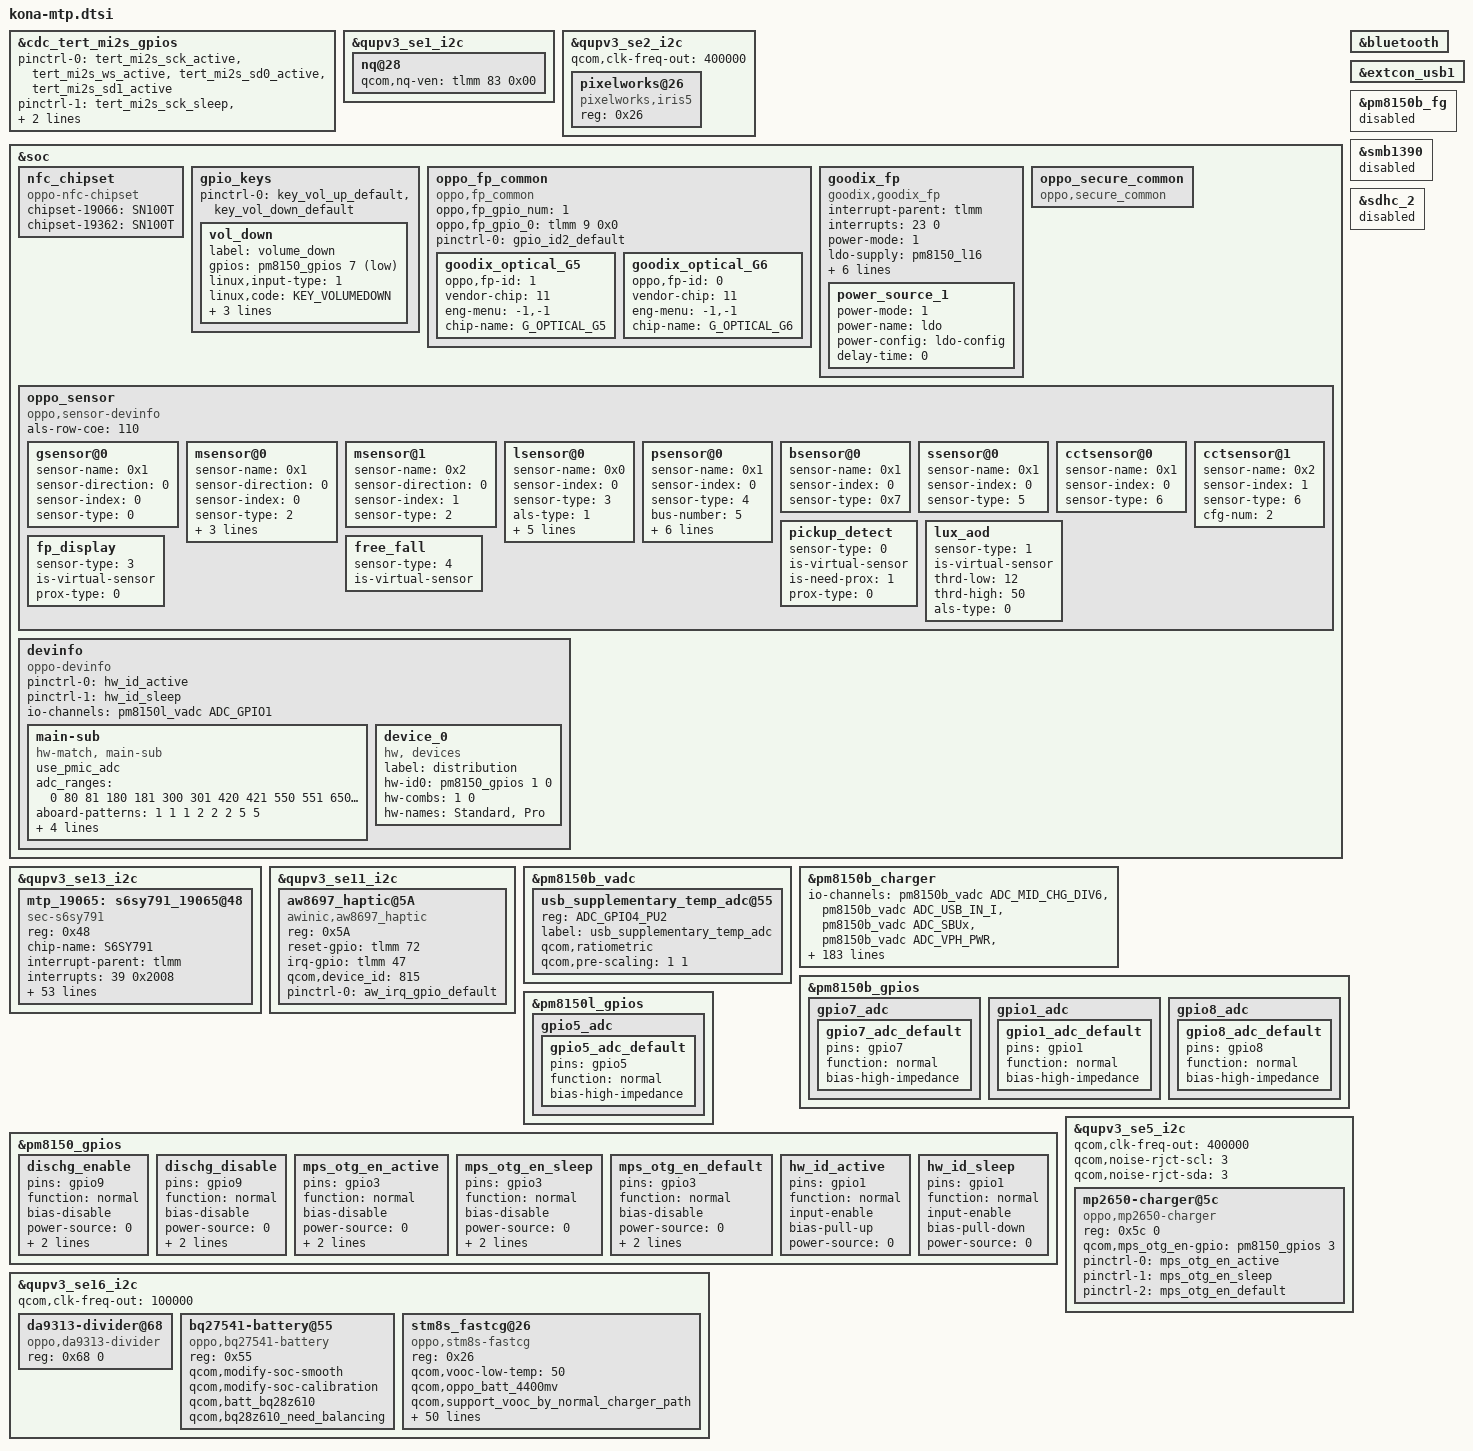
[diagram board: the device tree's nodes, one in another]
#include "kona-audio-overlay.dtsi"
#include "kona-camera-sensor-19066.dtsi"
#include "kona-pmic-overlay.dtsi"
#include "kona-sde-display.dtsi"

&cdc_tert_mi2s_gpios {
	pinctrl-0 = <&tert_mi2s_sck_active &tert_mi2s_ws_active
				&tert_mi2s_sd0_active &tert_mi2s_sd1_active>;
	pinctrl-1 = <&tert_mi2s_sck_sleep &tert_mi2s_ws_sleep
				&tert_mi2s_sd0_sleep &tert_mi2s_sd1_sleep>;
};

&qupv3_se1_i2c {
	/delete-property/ qcom,clk-freq-out;

	nq@28 {
		qcom,nq-ven = <&tlmm 83 0x00>;
	};
};

&qupv3_se2_i2c {
	status = "ok";
	qcom,clk-freq-out = <400000>;
	pixelworks@26 {  //i2c: 22, i3c: 26
		status = "ok";
		compatible = "pixelworks,iris5";
		reg = <0x26>;
	};
};

&soc {
	nfc_chipset {
		compatible = "oppo-nfc-chipset";
		chipset-19066 = "SN100T";
		chipset-19362 = "SN100T";
	};

	gpio_keys {
		pinctrl-0 = <&key_vol_up_default &key_vol_down_default>;

		vol_down {
			label = "volume_down";
			gpios = <&pm8150_gpios  7 GPIO_ACTIVE_LOW>;
			linux,input-type = <1>;
			linux,code = <KEY_VOLUMEDOWN>;
			gpio-key,wakeup;
			debounce-interval = <15>;
			linux,can-disable;
		};
	};

	oppo_fp_common {
		compatible = "oppo,fp_common";
		oppo,fp_gpio_num = <1>; /* the gpio number of fingerprint id used */
		oppo,fp_gpio_0 = <&tlmm 9 0x0>;
				pinctrl-names = "default";
		pinctrl-0 = <&gpio_id2_default>;
		goodix_optical_G5 {
			oppo,fp-id = <1>; /* fp id mapping table */
			vendor-chip = <11>; /* please refer to the struct fp_vendor_t in oppo_fp_commmon.n */
			eng-menu = "-1,-1"; /* represents SNR, inclination test item in engineer menu, and 0/1 means off/on */
			chip-name = "G_OPTICAL_G5";  /* /proc/fp_id, will be displayed in engineer menu  */
		};
		goodix_optical_G6 {
			oppo,fp-id = <0>; /* fp id mapping table */
			vendor-chip = <11>; /* please refer to the struct fp_vendor_t in oppo_fp_commmon.n */
			eng-menu = "-1,-1"; /* represents SNR, inclination test item in engineer menu, and 0/1 means off/on */
			chip-name = "G_OPTICAL_G6";  /* /proc/fp_id, will be displayed in engineer menu  */
		};
	};

	goodix_fp {
		status = "ok";
		compatible = "goodix,goodix_fp";
		interrupt-parent = <&tlmm>;
		interrupts = <23 0>;
		power-mode = <1> ; /*please refer to the struct fp_power_mode_t in oppo_fp_commmon.n ,0: power mode not set, 1: ldo power, 2: gpio power, 3: auto power */
		ldo-supply = <&pm8150_l16>;
		ldo-config = <3300000 3300000 150000>;
		goodix,gpio_irq = <&tlmm 23 0x1>;
		goodix,gpio_reset = <&tlmm 68 0x0>;
		pinctrl-names = "default";
		pinctrl-0 = <&gpio_goodix_irq_default>;
		notify_tpinfo_flag = <1>;
		power-num = <1>;
		power_source_1 {
			power-mode = <1>;
			power-name = "ldo";
			power-config = "ldo-config";
			delay-time = <0>;
		};
	};

	oppo_secure_common {
		compatible = "oppo,secure_common";
	};

	/*enum sensor_id { OPPO_ACCEL,OPPO_GYRO,OPPO_MAG,OPPO_LIGHT,OPPO_PROXIMITY,OPPO_SAR,OPPO_CT,OPPO_BAROMETER,SENSORS_NUM};*/
	oppo_sensor {
		compatible = "oppo,sensor-devinfo";
		als-row-coe = <110>;
		/*enum {LSM6DSM = 0x01, BMI160 = 0x02, LSM6DS3 = 0x04};*/
		gsensor@0 {
			sensor-name = <0x1>;//LSM6DSM
			sensor-direction = <0>;
			sensor-index = <0>;//source num
			sensor-type = <0>;//OPPO_ACCEL
		};
		/* enum {AKM0991X = 0x01, MMC5603 = 0x02};*/
		msensor@0 {
			sensor-name = <0x1>;//AKM09918
			sensor-direction = <0>;
			sensor-index = <0>;
			sensor-type = <2>;//OPPO_MAG
			parameter-number= <18>;
			//sensor-parameter = <1>;//0-useless;other- to differ special parameter
			soft-mag-parameter = <9887 0 1457 0 73 0 1262 0 10096 0 283 1 933 0 663 1 10867 0>;//e00 sign e01 sign...
		};
		msensor@1 {
			sensor-name = <0x2>;//MMC5603
			sensor-direction = <0>;
			sensor-index = <1>;
			sensor-type = <2>;//OPPO_MAG
		};
		/*enum {STK3A5X=0x01,TCS3701=0x02,TCS3408=0x04};*/
		lsensor@0 {
			sensor-name = <0x0>;//TCS3408 0-use other driver//compatible old
			sensor-index = <0>;
			sensor-type = <3>;//OPPO_LIGHT
			als-type = <1>;
			is-unit-device = <0>;
			is-als-dri = <0>;
			als-factor = <110>;
			is_als_initialed = <0>;
			als_buffer_length = <10>;
		};
		psensor@0 {
			sensor-name = <0x1>;//STK33502
			sensor-index = <0>;
			sensor-type = <4>;//OPPO_PROXIMITY
			bus-number = <5>;
			irq-number = <122>;
			ps-type = <1>;
			ps_saturation = <2600>;
			/*1-need close 2-close has contidition 0-not close*/
			is_need_close_pd = <2>;
			sn_number = <0xf2950863 0x09347b81 0xa5d679f5 0x5fe0fa1b 0xfcfb33ca
					0x85df9dee 0x30682ac0 0xddf4bc3d 0xb8d72979 0xe83f0a90
					0x24a9bcf0 0x77d4a0f0 0xb6870ef3 0x15e9693b 0x21858a59
					0x35a15be7 0x6c682a71 0x45e3d4ee>;
		};
		/*enum {LPS22HH = 0x01, BMP380 = 0x02}*/
		bsensor@0 {
			sensor-name = <0x1>;//LPS22HH
			sensor-index = <0>;
			sensor-type = <0x7>;//OPPO_BAROMETER
		};
		/* enum {SX9324 = 0x01} */
		ssensor@0 {
			sensor-name = <0x1>;//SX9324
			sensor-index = <0>;
			sensor-type = <5>;//OPPO_SAR
		};
		/* enum {tcs3408 = 0x01 tcs3408_rear = 0x02} */
		cctsensor@0 {
			sensor-name = <0x1>; //tcs3408
			sensor-index = <0>;
			sensor-type = <6>; //OPPO_CT
		};
		cctsensor@1 {
			sensor-name = <0x2>; //tcs3408_rear
			sensor-index = <1>;
			sensor-type = <6>; //OPPO_CT
			cfg-num = <2>;
		};
		/*virtual sensor
		enum sensor_algo_id {
			OPPO_PICKUP_DETECT,
			OPPO_LUX_AOD,
			OPPO_TP_GESTURE,
			OPPO_FP_DISPLAY,
			OPPO_FREE_FALL,
			OPPO_CAMERA_PROTECT,
			SENSOR_ALGO_NUM
		}*/
		pickup_detect {
			sensor-type = <0>;//OPPO_PICKUP_DETECT
			is-virtual-sensor;
			is-need-prox = <1>;
			prox-type = <0>;
		};
		lux_aod {
			sensor-type = <1>; //OPPO_LUX_AOD
			is-virtual-sensor;
			thrd-low = <12>;
			thrd-high = <50>;
			als-type = <0>;
		};
		fp_display {
			sensor-type = <3>;//OPPO_FP_DISPLAY
			is-virtual-sensor;
			prox-type = <0>; // 0 - proximity; 1 - proximity_fake
		};
		free_fall {
			sensor-type = <4>;//OPPO_FREE_FALL
			is-virtual-sensor;
		};
	};

	devinfo {
		compatible = "oppo-devinfo";

		pinctrl-names = "active", "sleep";
		pinctrl-0 = <&hw_id_active>;
		pinctrl-1 = <&hw_id_sleep>;

		io-channels= <&pm8150l_vadc ADC_GPIO1>;
		io-channel-names= "vph_pwr_voltage_sub";

		main-sub {
			compatible = "hw-match, main-sub";
			use_pmic_adc;
			adc_ranges = <0 80
						81 180
						181 300
						301 420
						421 550
						551 650
						651 760
						761 850
						851 950
						951 1050
						1051 1150
						1151 1300>;
			aboard-patterns = <1 1 1 2 2 2 5 5>;

			/*main board*/
			match-projects = <19066 19067 19362 19066 19067 19362 19066 19362>;

			/*rf type*/
			rf_match_support;
			rf-patterns = <0 2 1 3 4 6 7 8>;
		};

		device_0 {
			compatible = "hw, devices";
			label = "distribution";
			hw-id0 = <&pm8150_gpios 1 0>;
			hw-combs = <1 0>;
			hw-names = "Standard", "Pro";
		};
	};
};

&qupv3_se13_i2c {
	/delete-property/ qcom,i2s-touch-active;

	status = "okay";

	mtp_19065:s6sy791_19065@48 {
		compatible = "sec-s6sy791";
		reg = <0x48>;
		chip-name = "S6SY791";

		/* Interrupt && Irq-gpio */
		interrupt-parent = <&tlmm>;
		interrupts = <39 0x2008>;

		/* Power Config */
		//enable2v8_gpio = <&tlmm 26 0x1>;
		//enable1v8_gpio = <&tlmm 32 0x1>;
		vdd_2v8-supply = <&pm8150_l13>;
		vcc_1v8-supply = <&pm8150a_l1>;
		vdd_2v8_volt = <3008000>;

		/* Other HW Resource */
		irq-gpio = <&tlmm 39 0x2008>;
		reset-gpio = <&tlmm 38 0x1>;
		pinctrl-names = "default";
		pinctrl-0 = <&ts_int_active &ts_reset_active>;

				touchpanel,default_hor_area = <7>;
		touchpanel,max-num-support = <10>;
		touchpanel,tx-rx-num = <17 38>;
		earsense,tx-rx-num = <17 18>;
		touchpanel,panel-coords = <1440 3168>;
		touchpanel,display-coords = <1440 3168>;
		touchpanel,touchmajor-limit = <32 54>;
		project_id = <19065>;
				vid_len = <2>;
				tp_type = <8>; // TP-SAMSUNG = 8;
				platform_support_project = <19066 19067 19362>;
				platform_support_project_dir = <19065 19065 19065>;
				platform_support_project_commandline = "mdss_dsi_oppo19065_samsung_1440_3168_dsc_cmd","default_commandline","default_commandline" ;

		touchpanel,elimination-range = <20 200 200>;
		prevention,no_handle_para = <0 0 0>;
		prevention,dead_area_width = <20 10>;
		prevention,makeup_cnt_weight = <4 1 2 2 1>;
		prevention,large_judge_para = <18 40 40>;
		prevention,large_corner_judge_para = <60 0 0 0 0 0>;
		prevention,condition_judge_para = <60 0>;
		prevention,condition_area_width = <60 30 100 100>;
		prevention,large_area_width = <70 100>;
		prevention,large_corner_width = <100 200 0>;
		prevention,eli_area_width = <120 500 250 120>;
		prevention,grip_disable_level = <4>;
		prevention,grip_handle_in_fw;

		algorithm_stretch_cfg = <0 0 0 0 0
					 50 20 1 3068 3168
					 0 0 0 0 0
					 0 0 0 0 0>;
		algorithm_support;
		kalman_value = <2000 500 256 1024 0x10001>;

		/* SW Support Feature Control */
		//ear_sense_support;
		black_gesture_support;
		//fw_edge_limit_support;
		charger_pump_support;
		//spurious_fingerprint_support;
		fw_update_app_support;
		smart_gesture_support;
		game_switch_support;
		kernel_grip_support;
		fingerprint_underscreen_support;
		headset_pump_support;
		pressure_report_support;
		irq_need_dev_resume_ok;
		report_rate_white_list_support;

		/*
		 *Virtual Key Config:
		 *1:touchpanel,button-type: <virtualkey_type  supportted_button-map>
		 *virtualkey_type:
		 *Type 1: using board_properties
		 *Type 2: using same IC (button zone&& touch zone are seprate)
		 *Type 3: using diffrent IC (button zone&& touch zone are seprate)
		 *Type 4: No need of virtual key process
		 *supportted_button-map:select|menu|home|back
		 *
		 *2:touchpanel,button-map
		 *type (X1,Y1)(X2,Y2)(X3,Y3)(Width_X,Hight_Y)--Only when button-type is 0
		 */
		touchpanel,button-type = <4>;
		touchpanel.button-TRx = <0 0>;
	};
};

&bluetooth {
	/delete-property/ qca,bt-vdd-asd-supply;
};

&extcon_usb1 {
	/delete-property/ vbus-gpio;
	/delete-property/ vbus-out-gpio;
	/delete-property/ pinctrl-names;
	/delete-property/ pinctrl-0;
};

&qupv3_se11_i2c  {
	status = "ok";
		aw8697_haptic@5A {
				compatible = "awinic,aw8697_haptic";
				reg = <0x5A>;
				reset-gpio = <&tlmm 72 0>;
				irq-gpio = <&tlmm 47 0>;
				status = "ok";
				qcom,device_id = <815>;//19066

				pinctrl-names = "default";
				pinctrl-0 = <&aw_irq_gpio_default>;
		};
};

&pm8150b_vadc {
	usb_supplementary_temp_adc@55 {
		reg = <ADC_GPIO4_PU2>;
		label = "usb_supplementary_temp_adc";
		qcom,ratiometric;
		qcom,pre-scaling = <1 1>;
	};
};

&pm8150b_charger {
	io-channels = <&pm8150b_vadc ADC_MID_CHG_DIV6>,
			  <&pm8150b_vadc ADC_USB_IN_I>,
			  <&pm8150b_vadc ADC_SBUx>,
			  <&pm8150b_vadc ADC_VPH_PWR>,
			  <&pm8150b_vadc ADC_CHG_TEMP>,
			  <&pm8150b_vadc ADC_GPIO3>,
			  <&pm8150b_vadc ADC_AMUX_THM4_PU2>,
			  <&pm8150b_vadc ADC_GPIO4_PU2>;
	io-channel-names = "mid_voltage",
			   "usb_in_current",
			   "sbux_res",
			   "vph_voltage",
			   "chg_temp",
			   "chgID_voltage_adc",
			   "usb_temp_adc",
			   "usb_supplementary_temp_adc";
};

&pm8150b_fg {
	status = "disabled";
};

&smb1390 {
	status = "disabled";
};

&sdhc_2 {
	status = "disabled";
};

&pm8150b_gpios {
	gpio7_adc {
		gpio7_adc_default: gpio7_adc_default {
		pins = "gpio7"; /* GPIO 7 */
		function = "normal"; /* normal */
		bias-high-impedance; /* DISABLE GPIO7 for ADC*/
		};
	};
	gpio1_adc {
		gpio1_adc_default: gpio1_adc_default {
		pins = "gpio1"; /* GPIO 1 */
		function = "normal"; /* normal */
		bias-high-impedance; /* DISABLE GPIO1 for ADC*/
		};
	};
	gpio8_adc {
		gpio8_adc_default: gpio8_adc_default {
		pins = "gpio8"; /* GPIO 8 */
		function = "normal"; /* normal */
		bias-high-impedance; /* DISABLE GPIO8 for ADC*/
		};
	};

};

&pm8150l_gpios {
	gpio5_adc {
		gpio5_adc_default: gpio5_adc_default {
		pins = "gpio5"; /* GPIO 5 */
		function = "normal"; /* normal */
		bias-high-impedance; /* DISABLE GPIO5 for ADC*/
		};
	};
};

&pm8150_gpios {
	dischg_enable: dischg_enable {
		pins = "gpio9"; /* GPIO 9 */
		function = "normal"; /* normal */
		bias-disable; //No Pull
		power-source = <0>;//VIN0 3.3
		output-high; //digital output, no invert
		qcom,drive-strength = <3>; //LOW strength
		//drive-push-pull;//CMOS
	};

	dischg_disable: dischg_disable {
		pins = "gpio9"; /* GPIO 9 */
		function = "normal"; /* normal */
		bias-disable; //No Pull
		power-source = <0>;//VIN0 3.3
		output-low; //digital output, no invert
		qcom,drive-strength = <3>; //LOW strength
		//drive-push-pull;//CMOS
	};

	mps_otg_en_active: mps_otg_en_active {
		pins = "gpio3"; /* GPIO 3 */
		function = "normal"; /* normal */
		bias-disable; //No Pull
		power-source = <0>;//VIN1 1.8
		output-high; //digital output, no invert
		qcom,drive-strength = <3>; //LOW strength
		//drive-push-pull;//CMOS
	};
	mps_otg_en_sleep: mps_otg_en_sleep {
		pins = "gpio3"; /* GPIO 3 */
		function = "normal"; /* normal */
		bias-disable; //No Pull
		power-source = <0>;//VIN1 1.8
		output-low; //digital output, no invert
		qcom,drive-strength = <3>; //LOW strength
		//drive-push-pull;//CMOS
	};
	mps_otg_en_default: mps_otg_en_default {
		pins = "gpio3"; /* GPIO 3 */
		function = "normal"; /* normal */
		bias-disable; //No Pull
		power-source = <0>;//VIN1 1.8
		output-low; //digital output, no invert
		qcom,drive-strength = <3>; //LOW strength
		//drive-push-pull;//CMOS
	};

	hw_id_active: hw_id_active {
		pins = "gpio1"; /* GPIO 1 */
		function = "normal"; /* normal */
		input-enable;
		bias-pull-up;
		power-source = <0>;
	};

	hw_id_sleep: hw_id_sleep {
		pins = "gpio1"; /* GPIO 1 */
		function = "normal"; /* normal */
		input-enable;
		bias-pull-down;
		power-source = <0>;	/* 1.8V input supply */
	};
};

&qupv3_se5_i2c {
	status = "okay";
	qcom,clk-freq-out = <400000>;
	qcom,noise-rjct-scl = <3>;
	qcom,noise-rjct-sda = <3>;

	mp2650-charger@5c {
		status = "okay";
		compatible = "oppo,mp2650-charger";
		reg = <0x5c 0>;

		qcom,mps_otg_en-gpio = <&pm8150_gpios 3 0x00>;
		pinctrl-names = "mps_otg_en_active", "mps_otg_en_sleep", "mps_otg_en_default";
		pinctrl-0 = <&mps_otg_en_active>;
		pinctrl-1 = <&mps_otg_en_sleep>;
		pinctrl-2 = <&mps_otg_en_default>;

	};
};

&qupv3_se16_i2c {
	status = "okay";
	qcom,clk-freq-out = <100000>;

	da9313-divider@68 {
		status = "okay";
		compatible = "oppo,da9313-divider";
		reg = <0x68 0>;
	};

	bq27541-battery@55 {
		status = "okay";
		compatible = "oppo,bq27541-battery";
		reg = <0x55>;
		qcom,modify-soc-smooth;
		qcom,modify-soc-calibration;
		qcom,batt_bq28z610;
		qcom,bq28z610_need_balancing;
	};

	stm8s_fastcg@26{
		status = "okay";
		compatible = "oppo,stm8s-fastcg";
		reg = <0x26>;
		qcom,vooc-low-temp = <50>;
		qcom,oppo_batt_4400mv;
		qcom,support_vooc_by_normal_charger_path;
		qcom,vooc_fw_update_newmethod;
		qcom,vooc-high-temp = <430>;
		qcom,vooc-low-soc = <1>;
		qcom,vooc-high-soc = <90>;
		qcom,vooc-fw-type = <0x24>;//6A

		qcom,vooc_multistep_adjust_current_support;
		qcom,vooc_multistep_initial_batt_temp = <310>;
		qcom,vooc_strategy_normal_current = <0x06>;
		qcom,vooc-normal-to-little-cool-current = <0x05>;
		qcom,vooc_batt_over_high_temp = <440>;
		qcom,vooc_batt_over_low_temp = <45>;
		qcom,vooc_over_high_or_low_current = <0x0>;

		qcom,vooc_strategy1_batt_high_temp0 = <425>;
		qcom,vooc_strategy1_batt_high_temp1 = <430>;
		qcom,vooc_strategy1_batt_high_temp2 = <435>;
		qcom,vooc_strategy1_batt_low_temp2 = <420>;
		qcom,vooc_strategy1_batt_low_temp1 = <415>;
		qcom,vooc_strategy1_batt_low_temp0 = <400>;

		qcom,vooc_strategy1_high_current0 = <0x04>;//4A
		qcom,vooc_strategy1_high_current1 = <0x03>;//3A
		qcom,vooc_strategy1_high_current2 = <0x02>;//2A
		qcom,vooc_strategy1_low_current2 = <0x03>;//3A
		qcom,vooc_strategy1_low_current1 = <0x04>;//4A
		qcom,vooc_strategy1_low_current0 = <0x04>;//4A

		qcom,vooc_strategy2_batt_up_temp1 = <375>;
		qcom,vooc_strategy2_batt_up_down_temp2 = <380>;
		qcom,vooc_strategy2_batt_up_temp3 = <390>;
		qcom,vooc_strategy2_batt_up_down_temp4 = <400>;
		qcom,vooc_strategy2_batt_up_temp5 = <410>;
		qcom,vooc_strategy2_batt_up_temp6 = <415>;
		qcom,vooc_strategy2_high0_current = <0x05>;
		qcom,vooc_strategy2_high1_current = <0x04>;
		qcom,vooc_strategy2_high2_current = <0x03>;
		qcom,vooc_strategy2_high3_current = <0x02>;


		pinctrl-names = "switch1_act_switch2_act", "switch1_sleep_switch2_sleep",
						"switch1_act_switch3_act", "switch1_sleep_switch3_sleep",
						"switch1_act_switch2_sleep", "switch1_sleep_switch2_act",
						"clock_active","clock_sleep",
						"data_active","data_sleep",
						"reset_active","reset_sleep";
		pinctrl-0 = <&charging_switch1_active>;
		pinctrl-1 = <&charging_switch1_sleep >;
		pinctrl-2 = <&charging_switch1_active>;
		pinctrl-3 = <&charging_switch1_sleep >;
		pinctrl-4 = <&charging_switch1_active>;
		pinctrl-5 = <&charging_switch1_sleep>;
		pinctrl-6 = <&charging_clock_active >;
		pinctrl-7 = <&charging_clock_sleep >;
		pinctrl-8 = <&charging_data_active >;
		pinctrl-9 = <&charging_data_sleep >;
		pinctrl-10 = <&charging_reset_active >;
		pinctrl-11 = <&charging_reset_sleep >;

		qcom,charging_switch1-gpio = <&tlmm 82 0x00>;
		qcom,charging_reset-gpio = <&tlmm 10 0x00>;
		qcom,charging_clock-gpio = <&tlmm 131 0x00>;
		qcom,charging_data-gpio = <&tlmm 129 0x00>;
	};
};

&pm8150b_charger {
	//for smb5:
	qcom,usb-icl-ua = <2000000>;
	qcom,fcc-max-ua = <2000000>;
	qcom,qc3-disable;
	qcom,hvdcp-disable;
	qcom,float-option = <1>;
	qcom,oppo-pps-usbpd-detection = <&pm8150b_pdphy>;

	//for oppo chg framework:
	qcom,input_current_charger_ma = <2000>;
	qcom,pd_input_current_charger_ma = <2000>;
	qcom,qc_input_current_charger_ma = <2000>;
	qcom,input_current_usb_ma = <500>;
	qcom,input_current_cdp_ma = <1500>;
	qcom,input_current_led_ma = <1200>;
	qcom,input_current_led_ma_high = <1800>;
	qcom,input_current_led_ma_warm = <1800>;
	qcom,input_current_led_ma_normal = <2000>;
	qcom,led_warm_bat_decidegc = <350>;
	qcom,led_high_bat_decidegc = <370>;
	qcom,input_current_camera_ma = <1200>;
	qcom,input_current_vooc_led_ma_high = <1800>;
	qcom,input_current_vooc_led_ma_warm = <1800>;
	qcom,input_current_vooc_led_ma_normal = <3600>;
	qcom,input_current_vooc_ma_normal = <3600>;
	qcom,vooc_temp_bat_normal_decidegc = <350>;
	qcom,input_current_vooc_ma_warm = <3200>;
	qcom,vooc_temp_bat_warm_decidegc = <370>;
	qcom,input_current_vooc_ma_high = <2200>;
	qcom,vooc_temp_bat_hot_decidegc = <440>;
	qcom,charger_current_vooc_ma_normal = <1800>;
	qcom,chg_ctrl_by_calling;
	qcom,input_current_calling_ma = <1500>;

	qcom,overtemp_bat_decidegc = <350>;
	qcom,iterm_disabled = <0>;
	qcom,iterm_ma = <115>;
	qcom,recharge-mv = <100>;
	qcom,batt_capacity_mah = <4260>;/*typical capacity*/

	qcom,removed_bat_decidegc = <190>;  /*<-19C*/

	qcom,cold_bat_decidegc = <20>;  /*-2C~0C*/
	qcom,temp_cold_vfloat_mv = <3980>;
	qcom,temp_cold_fastchg_current_ma = <300>;

	qcom,little_cold_bat_decidegc = <0>;	/*0C~5C*/
	qcom,temp_little_cold_vfloat_mv = <4435>;
	qcom,temp_little_cold_fastchg_current_ma_high = <950>;
	qcom,temp_little_cold_fastchg_current_ma_low = <950>;
	qcom,temp_little_cold_fastchg_current_ma = <950>;
	qcom,pd_temp_little_cold_fastchg_current_ma_high = <1200>;
	qcom,pd_temp_little_cold_fastchg_current_ma_low = <950>;
	qcom,qc_temp_little_cold_fastchg_current_ma_high = <1200>;
	qcom,qc_temp_little_cold_fastchg_current_ma_low = <950>;

	qcom,cool_bat_decidegc = <50>;	/*5C~12C*/
	qcom,temp_cool_vfloat_mv = <4435>;
	qcom,temp_cool_fastchg_current_ma_high = <1100>;
	qcom,temp_cool_fastchg_current_ma_low = <1100>;
	qcom,pd_temp_cool_fastchg_current_ma_high = <1800>;
	qcom,pd_temp_cool_fastchg_current_ma_low = <1200>;
	qcom,qc_temp_cool_fastchg_current_ma_high = <1800>;
	qcom,qc_temp_cool_fastchg_current_ma_low = <1200>;

	qcom,little_cool_bat_decidegc = <120>;	/*12C~16C*/
	qcom,temp_little_cool_vfloat_mv = <4435>;
	qcom,temp_little_cool_fastchg_current_ma = <1100>;
	qcom,pd_temp_little_cool_fastchg_current_ma = <2000>;
	qcom,qc_temp_little_cool_fastchg_current_ma = <2000>;

	qcom,normal_bat_decidegc = <160>;	/*16C~44C*/
	qcom,temp_normal_fastchg_current_ma = <1100>;
	qcom,temp_normal_vfloat_mv = <4435>;
	qcom,pd_temp_normal_fastchg_current_ma = <2000>;
	qcom,qc_temp_normal_fastchg_current_ma = <2000>;

	qcom,warm_bat_decidegc = <450>;		/*45C~53C*/ /*8pin Bat Vooc project need add 3 degree C*/
	qcom,temp_warm_vfloat_mv = <4130>;
	qcom,temp_warm_fastchg_current_ma = <550>;
	qcom,pd_temp_warm_fastchg_current_ma = <550>;
	qcom,qc_temp_warm_fastchg_current_ma = <550>;
	qcom,temp_warm_fastchg_current_ma_led_on = <250>;

	qcom,hot_bat_decidegc = <530>;

	qcom,non_standard_vfloat_mv = <3980>;
	qcom,non_standard_fastchg_current_ma = <512>;

	qcom,short_c_bat_cv_mv = <4330>;
	qcom,short_c_bat_vfloat_mv = <3800>;
	qcom,short_c_bat_fastchg_current_ma = <512>;

	qcom,cold_vfloat_sw_limit = <3930>;
	qcom,little_cold_vfloat_sw_limit = <4385>;
	qcom,cool_vfloat_sw_limit = <4385>;
	qcom,little_cool_vfloat_sw_limit = <4385>;
	qcom,normal_vfloat_sw_limit = <4385>;
	qcom,warm_vfloat_sw_limit = <4080>;
	qcom,non_standard_vfloat_sw_limit = <3930>;
	qcom,short_c_bat_vfloat_sw_limit = <3750>;

	qcom,max_chg_time_sec = <36000>;
	qcom,charger_hv_thr = <9900>;
	qcom,charger_recv_thr = <9500>;
	qcom,charger_lv_thr = <3400>;
	qcom,vbatt_full_thr = <4435>;
	qcom,vbatt_hv_thr = <4600>;
	qcom,vfloat_step_mv = <8>;
	qcom,non_standard_vfloat_over_sw_limit = <3990>;
	qcom,cold_vfloat_over_sw_limit = <3990>;
	qcom,little_cold_vfloat_over_sw_limit = <4445>;
	qcom,cool_vfloat_over_sw_limit = <4445>;
	qcom,little_cool_vfloat_over_sw_limit = <4445>;
	qcom,normal_vfloat_over_sw_limit = <4445>;
	qcom,warm_vfloat_over_sw_limit = <4140>;

	qcom,vbatt_power_off = <3300>;
	qcom,vbatt_soc_1 = <3310>;
	qcom,vooc_project = <3>;
	qcom,vbatt_num = <2>;
	qcom,ffc_support;
	recharge_after_full;

	qcom,normal_vterm_hw_inc = <18>;
	qcom,non_normal_vterm_hw_inc = <18>;

	qcom,ff1_normal_fastchg_ma = <550>;
	qcom,ff1_warm_fastchg_ma = <550>;
	qcom,ffc2_normal_fastchg_ma = <300>;/*12C~35c*/
	qcom,ffc2_temp_warm_decidegc = <350>;
	qcom,ffc2_warm_fastchg_ma = <350>;/*35C~40c*/
	qcom,ffc2_temp_high_decidegc = <400>;
	qcom,ffc2_temp_low_decidegc = <120>;
	qcom,ffc2_exit_step_ma = <100>;
	qcom,ff1_exit_step_ma = <150>;
	qcom,ff1_warm_exit_step_ma = <150>;

	qcom,ffc_normal_vfloat_sw_limit = <4455>;
	qcom,ffc2_normal_vfloat_sw_limit = <4445>;
	qcom,ffc2_warm_vfloat_sw_limit = <4445>;
	qcom,ffc_temp_normal_vfloat_mv = <4500>;
	qcom,ffc1_temp_normal_vfloat_mv = <4500>;
	qcom,ffc2_temp_normal_vfloat_mv = <4500>;
	qcom,ffc_normal_vfloat_over_sw_limit = <4500>;
	qcom,ffc1_normal_vfloat_over_sw_limit = <4500>;
	qcom,ffc2_normal_vfloat_over_sw_limit = <4500>;

	qcom,default_iterm_ma = <115>;
	qcom,default_temp_normal_fastchg_current_ma = <1100>;
	qcom,default_normal_vfloat_sw_limit = <4385>;
	qcom,default_temp_normal_vfloat_mv = <4435>;
	qcom,default_normal_vfloat_over_sw_limit = <4445>;

	qcom,default_temp_little_cool_fastchg_current_ma = <1100>;
	qcom,default_little_cool_vfloat_sw_limit = <4385>;
	qcom,default_temp_little_cool_vfloat_mv = <4435>;
	qcom,default_little_cool_vfloat_over_sw_limit = <4445>;

	//for control:
	qcom,check_batt_full_by_sw;
	qcom,external_gauge;
	qcom,chg_ctrl_by_lcd;
	qcom,chg_ctrl_by_vooc;
	qcom,chg_ctrl_by_camera;
	qcom,sw_vfloat_over_protect_enable;
	qcom,lpd-disable;

	//for PD9V or QC9V
	qcom,vbatt_pdqc_to_5v_thr = <4180>;

	qcom,vooc_show_ui_soc_decimal;
	qcom,ui_soc_decimal_speedmin = <20>;//2A

	qcom,chargerid_switch-gpio = <&tlmm 50 0x00>;
	qcom,ship-gpio = <&tlmm 22 0x00>;
	qcom,ccdetect-gpio = <&tlmm 14 0x00>;
	qcom,dischg-gpio = <&pm8150_gpios 9 0x00>;

	pinctrl-names = "default",
			"chargerid_switch_active",
			"chargerid_switch_sleep",
			"chargerid_switch_default",
			"ship_active", "ship_sleep",
			"ccdetect_active", "ccdetect_sleep",
			"dischg_enable", "dischg_disable",
			"gpio1_adc_default","gpio8_adc_default",
			"gpio5_adc_default",
			"charger_int_default",
			"input_pg_default",
			"charger_error_default";

	pinctrl-0 = <&gpio7_adc_default>;
	pinctrl-1 = <&chargerid_switch_active>;
	pinctrl-2 = <&chargerid_switch_sleep>;
	pinctrl-3 = <&chargerid_switch_default>;
	pinctrl-4 = <&ship_active>;
	pinctrl-5 = <&ship_sleep>;
	pinctrl-6 = <&ccdetect_active>;
	pinctrl-7 = <&ccdetect_sleep>;
	pinctrl-8 = <&dischg_enable>;
	pinctrl-9 = <&dischg_disable>;
	pinctrl-10 = <&gpio1_adc_default>;
	pinctrl-11 = <&gpio8_adc_default>;
	pinctrl-12 = <&gpio5_adc_default>;
	pinctrl-13 = <&charger_int_default>;
	pinctrl-14 = <&input_pg_default>;
	pinctrl-15 = <&charger_error_default>;
};
